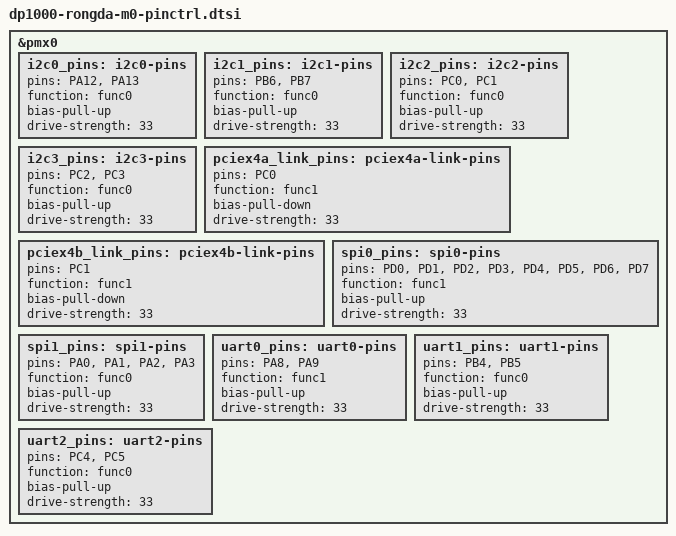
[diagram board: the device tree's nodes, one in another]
// SPDX-License-Identifier: GPL-2.0
/*
 * Copyright(C) 2026 UltraRISC Technology (Shanghai) Co., Ltd.
 */

#include "dp1000.dtsi"

&pmx0 {
	i2c0_pins: i2c0-pins {
		pins = "PA12", "PA13";
		function = "func0";
		bias-pull-up;
		drive-strength = <33>;
	};

	i2c1_pins: i2c1-pins {
		pins = "PB6", "PB7";
		function = "func0";
		bias-pull-up;
		drive-strength = <33>;
	};

	i2c2_pins: i2c2-pins {
		pins = "PC0", "PC1";
		function = "func0";
		bias-pull-up;
		drive-strength = <33>;
	};

	i2c3_pins: i2c3-pins {
		pins = "PC2", "PC3";
		function = "func0";
		bias-pull-up;
		drive-strength = <33>;
	};

	pciex4a_link_pins: pciex4a-link-pins {
		pins = "PC0";
		function = "func1";
		bias-pull-down;
		drive-strength = <33>;
	};

	pciex4b_link_pins: pciex4b-link-pins {
		pins = "PC1";
		function = "func1";
		bias-pull-down;
		drive-strength = <33>;
	};

	spi0_pins: spi0-pins {
		pins = "PD0", "PD1", "PD2", "PD3", "PD4", "PD5", "PD6", "PD7";
		function = "func1";
		bias-pull-up;
		drive-strength = <33>;
	};

	spi1_pins: spi1-pins {
		pins = "PA0", "PA1", "PA2", "PA3";
		function = "func0";
		bias-pull-up;
		drive-strength = <33>;
	};

	uart0_pins: uart0-pins {
		pins = "PA8", "PA9";
		function = "func1";
		bias-pull-up;
		drive-strength = <33>;
	};

	uart1_pins: uart1-pins {
		pins = "PB4", "PB5";
		function = "func0";
		bias-pull-up;
		drive-strength = <33>;
	};

	uart2_pins: uart2-pins {
		pins = "PC4", "PC5";
		function = "func0";
		bias-pull-up;
		drive-strength = <33>;
	};
};
